AUTOSAR XML (schema 00051)
package /ComponentTypes
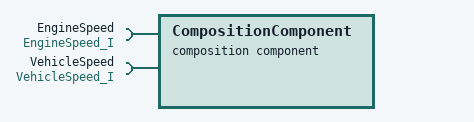
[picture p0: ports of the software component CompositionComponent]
  composition sw component type CompositionComponent
    require port EngineSpeed: nonqueued-receiver-com-spec{data-element=EngineSpeed, init-value=constant-reference=EngineSpeed_IV}, required-interface=EngineSpeed_I
    require port VehicleSpeed: nonqueued-receiver-com-spec{data-element=VehicleSpeed, init-value=constant-reference=VehicleSpeed_IV}, required-interface=VehicleSpeed_I
    component ReceiverComponent: type=ReceiverComponent
    component TimerComponent: type=TimerComponent
    connect TimerComponent.FreeRunningTimer -> ReceiverComponent.FreeRunningTimer
    delegate ReceiverComponent.VehicleSpeed <-> outer port VehicleSpeed
    delegate ReceiverComponent.EngineSpeed <-> outer port EngineSpeed
